# R40 register map
Vendor: Allwinner; Series: R40; File version: 0.1
CPU: CA7 0, little endian, MPU, FPU, double-precision FPU, 0 interrupt priority bits
Registers are 32-bit, read-write, reset 0x0 unless marked. A register's access mark holds for its fields unless they carry their own. Offsets are from the block's base; [hi:lo] are bit positions; lines under a group give offsets from that group; {n}, {i} and the like mark numbered series; 'fields as' and 'values as' point back to an identical list.

## CSI0
Base 0x01C09000
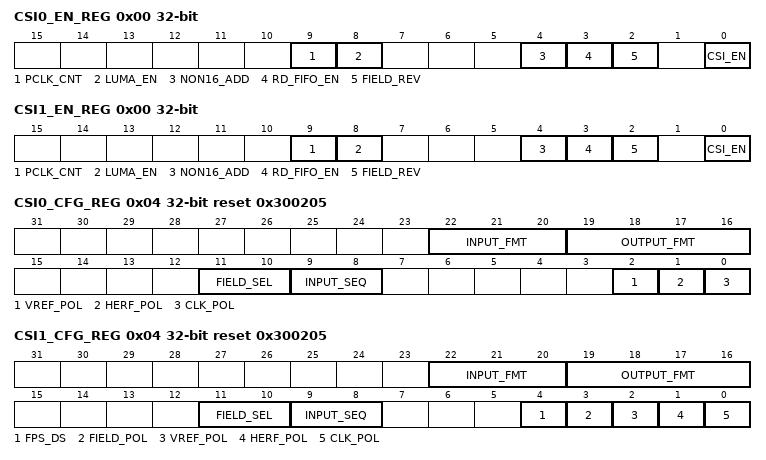
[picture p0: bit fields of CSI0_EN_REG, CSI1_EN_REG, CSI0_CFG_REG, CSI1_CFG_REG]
0x00 CSI0_EN_REG — CSI Enable Register
  [9] PCLK_CNT — Pclk count per frame
  [8] LUMA_EN — Luma enable
  [4] NON16_ADD — Non-16 add 0x00
  [3] RD_FIFO_EN — Read fifo [3]fifo enable, fifo address[01c09800~01c09ffc]
  [2] FIELD_REV — CCIR656 field_reverse
  [0] CSI_EN — Enable 0: Reset and disable the CSI module 1: Enable the CSI module
    0=Reset and disable the CSI module; 1=Enable the CSI module
0x00 CSI1_EN_REG — CSI Enable Register
  fields as CSI0_EN_REG
0x04 CSI0_CFG_REG reset 0x300205 — CSI Configuration Register
  [22:20] INPUT_FMT — Input data format 000: RAW stream 001: reserved 010: CCIR656(one channel 011: YUV422 100: YUV422 16bit data bus 101: two channel CCIR656 110: reserved 111: four channel CCIR656
  [19:16] OUTPUT_FMT — Output data format When the input format is set RAW stream 0000: pass-through When the input format is set CCIR656 interface 0000: field planar YCbCr 422 0001: field planar YCbCr 420 0010: frame planar YCbCr 420 0011: frame planar YCbCr 422 0100: field planar YCbCr 422 UV combined 0101: field planar YCbCr 420 UV combined 0110: frame planar YCbCr 420 UV combined 0111: frame planar YCbCr 422 UV combined 1111: interlaced interleaved YCbCr422. In this mode, capturing interlaced input and output the interlaced fields from individual ports. Field 1 data will be written to FIFO0 output buffer and field 2 data will be written to FIFO1 output buffer. 1000: field MB YCbCr 422 1001: field MB YCbCr 420 1010: frame MB YCbCr 420 1011: frame MB YCbCr 422 When the input format is set YUV422 0000: planar YUV 422 0001: planar YUV 420 0100: planar YUV 422 UV combined 0101: planar YUV 420 UV combined 1000: MB YUV 422 1001: MB YUV 420
  [11:10] FIELD_SEL — Field selection. Applies to CCIR656 interface only. 00: start capturing with field 1. 01: start capturing with field 2. 10: start capturing with either field. 11: reserved
    0=start_capturing_with_field_1; 1=start_capturing_with_field_2; 2=start_capturing_with_either_field
  [9:8] INPUT_SEQ — Input data sequence, only valid for YUV422 mode. 00: YUYV 01: YVYU 10: UYVY 11: VYUY
    0=YUYV; 1=YVYU; 2=UYVY; 3=VYUY
  [2] VREF_POL — Vref polarity 0: negative 1: positive This register is not applied to CCIR656 interface.
    0=negative; 1=positive This register is not applied to CCIR656 interface
  [1] HERF_POL — Href polarity 0: negative 1: positive This register is not applied to CCIR656 interface.
    values as VREF_POL
  [0] CLK_POL — Data clock type 0: active in rising edge 1: active in falling edge
    0=active_in_rising_edge; 1=active_in_falling_edge
0x04 CSI1_CFG_REG reset 0x300205 — CSI Configuration Register
  [22:20] INPUT_FMT — Input data format 000: RAW stream 001: reserved 010: CCIR656(one channel) 011: YUV422 100: YUV444({R, B, G} or {Pr, Pb, Y}) 101: two channel CCIR656 110: reserved 111: four channel CCIR656
    0=RAW (RAW stream); 2=CCIR656_openingparen_one (CCIR656(one channel)); 3=YUV422; 4=YUV444_openingparen__openingbrace_R (YUV444({R, B, G} or {Pr, Pb, Y})); 5=two (two channel CCIR656); 7=four channel CCIR656
  [19:16] OUTPUT_FMT — Output data format When the input format is set RAW stream 0000: pass-through When the input format is set CCIR656 interface 0000: field planar YCbCr 422 0001: field planar YCbCr 420 0010: frame planar YCbCr 420 0011: frame planar YCbCr 422 0100: field planar YCbCr 422 UV combined 0101: field planar YCbCr 420 UV combined 0110: frame planar YCbCr 420 UV combined 0111: frame planar YCbCr 422 UV combined 1111: interlaced interleaved YCbCr422. In this mode, capturing interlaced input and output the interlaced fields from individual ports. Field 1 data will be written to FIFO0 output buffer and field 2 data will be written to FIFO1 output buffer. 1000: field MB YCbCr 422 1001: field MB YCbCr 420 1010: frame MB YCbCr 420 1011: frame MB YCbCr 422 When the input format is set YUV422 0000: planar YUV 422 0001: planar YUV 420 0100: planar YUV 422 UV combined 0101: planar YUV 420 UV combined 1000: MB YUV 422 1001: MB YUV 420 When the input format is set YUV444 1100: field planar YUV 444 1101: field planar YUV 422 UV combined 1110: frame planar YUV 444 1111: frame planar YUV 422 UV combined
  [11:10] FIELD_SEL — Field selection. Applies to CCIR656 interface only. 00: start capturing with field 1. 01: start capturing with field 2. 10: start capturing with either field. 11: reserved
    values as CSI0_CFG_REG.FIELD_SEL
  [9:8] INPUT_SEQ — Input data sequence, only valid for YUV422 mode. 00: YUYV 01: YVYU 10: UYVY 11: VYUY
    0=YUYV; 1=YVYU; 2=UYVY; 3=VYUY
  [4] FPS_DS — Fps down sample 0: no down sample 1: 1/2 fps, only receives the first frame every 2 frames
    0=no down sample; 1=_1_slash_2 (1/2 fps, only receives the first frame every 2 frames)
  [3] FIELD_POL — Field polarity 0: negative(field=0 indicate odd, field=1 indicate even ) 1: positive(field=1 indicate odd, field=0 indicate even ) This register is not applied to CCIR656 interface.
    0=negative_openingparen_field_equals_0 (negative(field=0 indicate odd, field=1 indicate even )); 1=positive_openingparen_field_equals_1 (positive(field=1 indicate odd, field=0 indicate even ) This register is not applied to CCIR656 interface.)
  [2] VREF_POL — Vref polarity 0: negative 1: positive This register is not applied to CCIR656 interface.
    values as CSI0_CFG_REG.VREF_POL
  [1] HERF_POL — Href polarity 0: negative 1: positive This register is not applied to CCIR656 interface.
    values as CSI0_CFG_REG.VREF_POL
  [0] CLK_POL — Data clock type 0: active in rising edge 1: active in falling edge
    0=active_in_rising_edge; 1=active_in_falling_edge
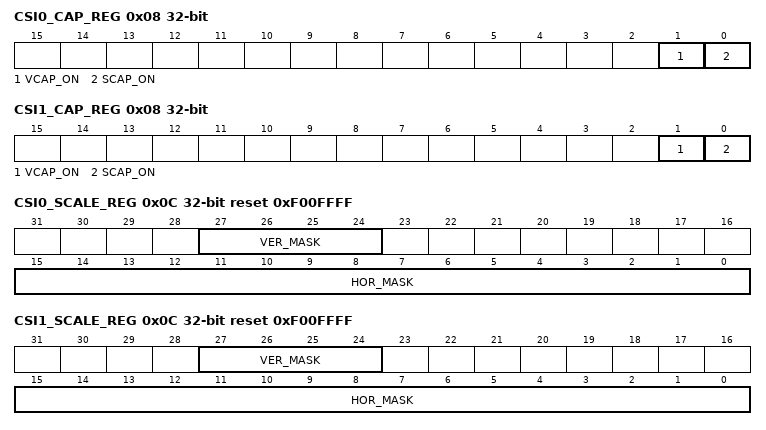
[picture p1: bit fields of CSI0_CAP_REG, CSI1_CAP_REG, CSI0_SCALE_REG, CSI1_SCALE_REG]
0x08 CSI0_CAP_REG — CSI Capture Control Register
  [1] VCAP_ON — Video capture control: Capture the video image data stream. 0: Disable video capture If video capture is in progress, the CSI stops capturing image data at the end of the current frame, and all of the current frame data is written to output FIFO. 1: Enable video capture The CSI starts capturing image data at the start of the next frame.
    0=Disable video capture If video capture is in progress, the CSI stops capturing image data at the end of the current frame, and all of the current frame data is written to output FIFO; 1=Enable video capture The CSI starts capturing image data at the start of the next frame
  [0] SCAP_ON — Still capture control: Capture a single still image frame. 0: Disable still capture. 1: Enable still capture The CSI module starts capturing image data at the start of the next frame. The CSI module captures only one frame of image data. This bit is self cleared, and it always reads as a 0.
    0=Disable still capture; 1=Enable still capture The CSI module starts capturing image data at the start of the next frame. The CSI module captures only one frame of image data. This bit is self cleared, and it always reads as a 0.
0x08 CSI1_CAP_REG — CSI Capture Control Register
  [1] VCAP_ON — Video capture control: Capture the video image data stream. 0: Disable video capture If video capture is in progress, the CSI stops capturing image data at the end of the current frame, and all of the current frame data is written to output FIFO. 1: Enable video capture The CSI starts capturing image data at the start of the next frame.
    values as CSI0_CAP_REG.VCAP_ON
  [0] SCAP_ON — Still capture control: Capture a single still image frame. 0: Disable still capture. 1: Enable still capture The CSI module starts capturing image data at the start of the next frame. The CSI module captures only one frame of image data. This bit is self cleared ,and it always reads as a 0.
    0=Disable still capture; 1=Enable still capture The CSI module starts capturing image data at the start of the next frame. The CSI module captures only one frame of image data. This bit is self cleared ,and it always reads as a 0.
0x0C CSI0_SCALE_REG reset 0xF00FFFF — CSI Scale Register
  [27:24] VER_MASK — Vertical (line) mask. Every 4-line is a mask group. Bit 24 mask the first line, bit 25 mask the second line, and so on. Mask bit = 0 means discarding this line data.
  [15:0] HOR_MASK — Horizontal (datastream) mask. Every 16-byte is a mask group. Bit 0 masks the first byte, bit 1 masks the second byte, and so on. Mask bit = 0 means discarding this byte from the datastream.
0x0C CSI1_SCALE_REG reset 0xF00FFFF — CSI Scale Register
  [27:24] VER_MASK — Vertical (line) mask. Every 4-line is a mask group. Bit 24 masks the first line, bit 25 masks the second line, and so on. Mask bit = 0 means discarding this line data.
  [15:0] HOR_MASK — Horizontal (datastream) mask. Every 16-byte is a mask group. Bit 0 masks the first byte, bit 1 masks the second byte, and so on. Mask bit = 0 means discarding this byte from the datastream.
{0x10+0x100*i} _N[{i}] (i=0..3) group
  {0x0+8j} CSI0_F{j}_BUFA_REG (j=0..2) — CSI Channel_N FIFO {j} Output Buffer-A Address Register
    [31:0] C0F{j}_BUFA — FIFO {j} output buffer-A address
  {0x4+8j} CSI0_F{j}_BUFB_REG (j=0..2) — CSI Channel_N FIFO {j} Output Buffer-B Address Register
    [31:0] C0F{j}_BUFB — FIFO {j} output buffer-B address
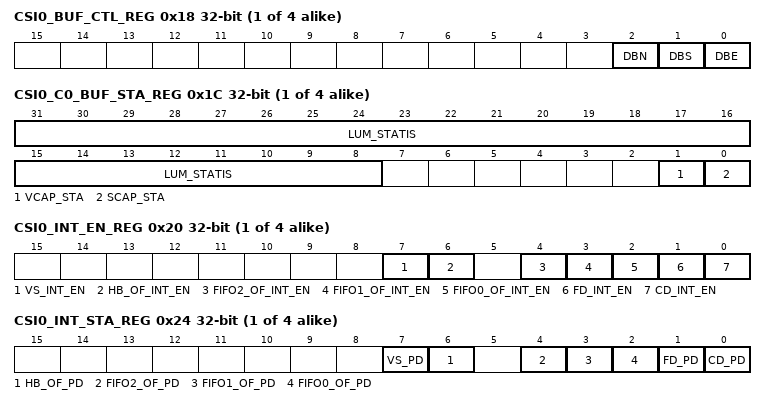
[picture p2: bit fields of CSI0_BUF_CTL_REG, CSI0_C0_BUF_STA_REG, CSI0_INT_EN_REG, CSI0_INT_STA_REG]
  0x18 CSI0_BUF_CTL_REG — CSI Channel_N Output Buffer Control Register
    [2] DBN — Buffer selected at next storing for CSI 0: Next buffer selection is buffer-A 1: Next buffer selection is buffer-B
      0=buffer_minus_A (Next buffer selection is buffer-A); 1=buffer_minus_B (Next buffer selection is buffer-B)
    [1] DBS ro — Output buffer selected status 0: Selected output buffer-A 1: Selected output buffer-B
      0=Selected_output_buffer_minus_A (Selected output buffer-A); 1=Selected_output_buffer_minus_B (Selected output buffer-B)
    [0] DBE — Double buffer mode enable 0: Disable 1: Enable If the double buffer mode is disabled, the buffer-A will be always selected by CSI module.
      0=Disable; 1=Enable If the double buffer mode is disabled, the buffer-A will be always selected by CSI module
  0x1C CSI0_C0_BUF_STA_REG
    [31:8] LUM_STATIS ro — luminance statistical value When frame done interrupt flag come, the value is ready and will last until next frame done. For raw data, value = (G>>1+R+G)>>8 For yuv422, value = Y>>8
    [1] VCAP_STA ro — Video capture in progress Indicates the CSI is capturing video image data (multiple frames). The bit is set at the start of the first frame after enabled video capture. When software disables video capture, it clears itself after the last pixel of the current frame is captured.
    [0] SCAP_STA ro — Still capture in progress Indicates the CSI is capturing still image data (single frame). The bit is set at the start of the first frame after enabled still frame capture. It clears itself after the last pixel of the first frame is captured. For CCIR656 interface, if the output format is frame planar YCbCr 420 mode, the frame end means the field2 end, the other frame end means filed end.
  0x20 CSI0_INT_EN_REG — CSI Channel_N Interrupt Enable Register
    [7] VS_INT_EN — vsync flag The bit is set when vsync come. And at this time load the buffer address for the coming frame. So after this irq come, change the buffer address could only effect next frame
    [6] HB_OF_INT_EN — Hblank FIFO overflow The bit is set when 3 FIFOs still overflow after the hblank.
    [4] FIFO2_OF_INT_EN — FIFO 2 overflow The bit is set when the FIFO 2 become overflow.
    [3] FIFO1_OF_INT_EN — FIFO 1 overflow The bit is set when the FIFO 1 become overflow.
    [2] FIFO0_OF_INT_EN — FIFO 0 overflow The bit is set when the FIFO 0 become overflow.
    [1] FD_INT_EN — Frame done Indicates the CSI has finished capturing an image frame. Applies to video capture mode. The bit is set after each completed frame capturing data is written to buffer as long as video capture remains enabled.
    [0] CD_INT_EN — Capture done Indicates the CSI has completed capturing the image data. For still capture, the bit is set when one frame data has been written to buffer. For video capture, the bit is set when the last frame has been written to buffer after video capture has been disabled. For CCIR656 interface, if the output format is frame planar YCbCr 420 mode, the frame end means the field2 end, the other frame end means field end.
  0x24 CSI0_INT_STA_REG — CSI Channel_N Interrupt Status Register
    [7] VS_PD write-1-clears — vsync flag
    [6] HB_OF_PD write-1-clears — Hblank FIFO overflow
    [4] FIFO2_OF_PD write-1-clears — FIFO 2 overflow
    [3] FIFO1_OF_PD write-1-clears — FIFO 1 overflow
    [2] FIFO0_OF_PD write-1-clears — FIFO 0 overflow
    [1] FD_PD write-1-clears — Frame done
    [0] CD_PD write-1-clears — Capture done
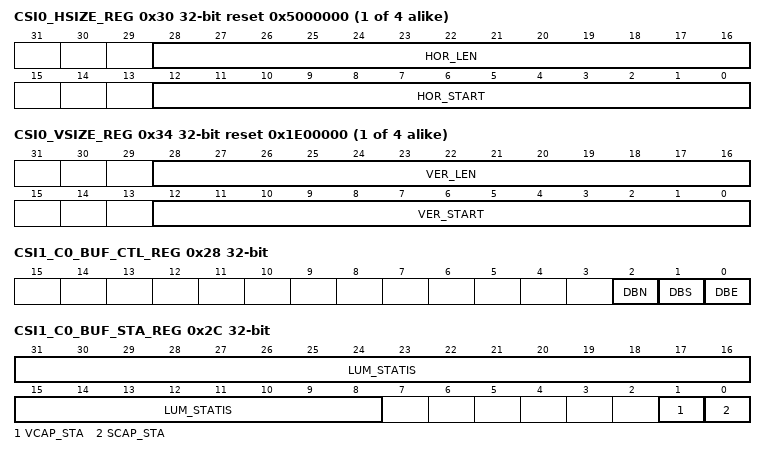
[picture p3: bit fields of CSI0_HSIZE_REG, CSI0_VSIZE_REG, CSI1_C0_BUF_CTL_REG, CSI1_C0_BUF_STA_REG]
  0x30 CSI0_HSIZE_REG reset 0x5000000 — CSI Channel_N Horizontal Size Register
    [28:16] HOR_LEN — Horizontal pixel clock length. Valid pixel clocks of a line.
    [12:0] HOR_START — Horizontal pixel clock start.Pixel data is valid from this clock.
  0x34 CSI0_VSIZE_REG reset 0x1E00000 — CSI Channel_N Vertical Size Register
    [28:16] VER_LEN — Vertical line length. Valid line number of a frame.
    [12:0] VER_START — Vertical line start. Data is valid from this line.
  0x38 CSI0_BUF_LEN_REG reset 0x280 — CSI Channel_N Line Buffer Length Register
    [12:0] BUF_LEN — Buffer length of a line. Unit is byte. It is the max of the 3 FIFOs
{0x10+8i} CSI1_C0_F{i}_BUFA_REG (i=0..2)
  [31:0] C0F{i}_BUFA — FIFO {i} output buffer-A address
{0x14+8i} CSI1_C0_F{i}_BUFB_REG (i=0..2)
  [31:0] C0F{i}_BUFB — FIFO {i} output buffer-B address
0x28 CSI1_C0_BUF_CTL_REG
  [2] DBN — Buffer selected at next storing for CSI 0: Next buffer selection is buffer-A 1: Next buffer selection is buffer-B
    values as _N[0].CSI0_BUF_CTL_REG.DBN
  [1] DBS ro — output buffer selected status 0: Selected output buffer-A 1: Selected output buffer-B
    values as _N[0].CSI0_BUF_CTL_REG.DBS
  [0] DBE — Double buffer mode enable 0: Disable 1: Enable If the double buffer mode is disabled, the buffer-A will be always selected by CSI module.
    values as _N[0].CSI0_BUF_CTL_REG.DBE
0x2C CSI1_C0_BUF_STA_REG
  [31:8] LUM_STATIS ro — Luminance statistical value When frame done interrupt flag come, value is ready and will last until next frame done. For raw data, value = (G>>1+R+G)>>8 For yuv422, value = Y>>8
  [1] VCAP_STA ro — Video capture in progress Indicates the CSI is capturing video image data (multiple frames). The bit is set at the start of the first frame after enabling video capture. When software disables video capture, it clears itself after the last pixel of the current frame is captured.
  [0] SCAP_STA ro — Still capture in progress Indicates the CSI is capturing still image data (single frame). The bit is set at the start of the first frame after enabling still frame capture. It clears itself after the last pixel of the first frame is captured. For CCIR656 interface, if the output format is frame planar YCbCr 420 mode, the frame end means the field2 end, the other frame end means filed end.
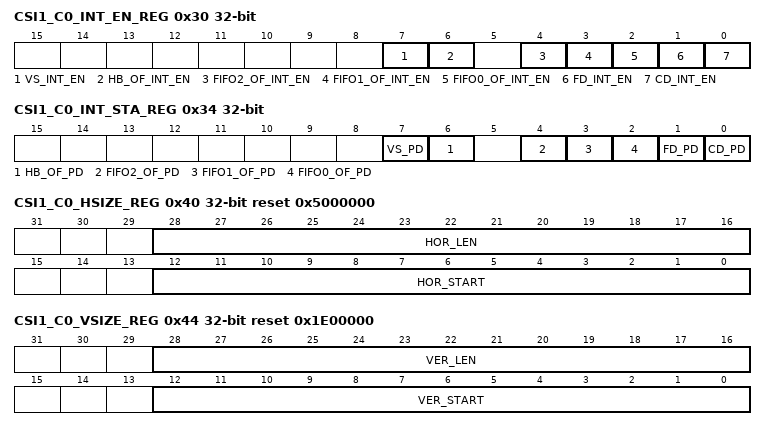
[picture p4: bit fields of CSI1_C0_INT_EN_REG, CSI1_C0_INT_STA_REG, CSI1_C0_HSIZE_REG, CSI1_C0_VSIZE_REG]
0x30 CSI1_C0_INT_EN_REG
  fields as _N[0].CSI0_INT_EN_REG
0x34 CSI1_C0_INT_STA_REG
  fields as _N[0].CSI0_INT_STA_REG
0x40 CSI1_C0_HSIZE_REG reset 0x5000000
  fields as _N[0].CSI0_HSIZE_REG
0x44 CSI1_C0_VSIZE_REG reset 0x1E00000
  [28:16] VER_LEN — Vertical line length. Valid line number of a frame.
  [12:0] VER_START — Vertical line start. data is valid from this line.
0x48 CSI1_C0_BUF_LEN_REG reset 0x280
  fields as _N[0].CSI0_BUF_LEN_REG
